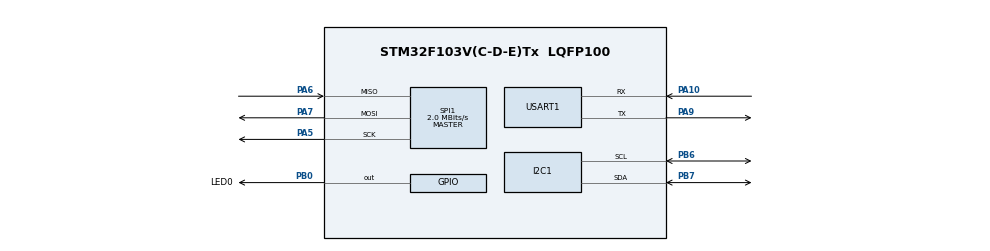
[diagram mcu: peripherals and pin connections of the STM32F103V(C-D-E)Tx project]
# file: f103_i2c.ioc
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Mcu.Family=STM32F1
PA6.Mode=Full_Duplex_Master
PA7.Mode=Full_Duplex_Master
PA10.Mode=Asynchronous
SPI1.VirtualType=VM_MASTER
PB0.GPIO_Label=LED0
SPI1.CLKPhase=SPI_PHASE_2EDGE
ProjectManager.StackSize=0x400
PA13.Signal=SYS_JTMS-SWDIO
PA9.Mode=Asynchronous
SPI1.CLKPolarity=SPI_POLARITY_HIGH
ProjectManager.TargetToolchain=MDK-ARM V5.27
SPI1.Direction=SPI_DIRECTION_2LINES
PA9.Signal=USART1_TX
PB6.Signal=I2C1_SCL
PB6.Mode=I2C
SPI1.CalculateBaudRate=2.0 MBits/s
PA5.Signal=SPI1_SCK
board=custom
RCC.APB2Freq_Value=8000000
SPI1.CRCCalculation=SPI_CRCCALCULATION_DISABLE
SPI1.Mode=SPI_MODE_MASTER
PA14.Mode=Serial_Wire
PB7.Signal=I2C1_SDA
PA13.Mode=Serial_Wire
Mcu.Name=STM32F103V(C-D-E)Tx
Mcu.Package=LQFP100
PA6.Signal=SPI1_MISO
USART1.VirtualMode=VM_ASYNC
PB7.Mode=I2C
PA10.Signal=USART1_RX
PA14.Signal=SYS_JTCK-SWCLK
ProjectManager.HeapSize=0x200
NVIC.PriorityGroup=NVIC_PRIORITYGROUP_4
RCC.APB1Freq_Value=8000000
SPI1.BaudRatePrescaler=SPI_BAUDRATEPRESCALER_4
PB0.Signal=GPIO_Output
PA5.Mode=Full_Duplex_Master
PA7.Signal=SPI1_MOSI

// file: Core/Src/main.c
/* USER CODE BEGIN Header */
/**
  ******************************************************************************
  * @file           : main.c
  * @brief          : Main program body
  ******************************************************************************
  * @attention
  *
  * <h2><center>&copy; Copyright (c) 2020 STMicroelectronics.
  * All rights reserved.</center></h2>
  *
  * This software component is licensed by ST under BSD 3-Clause license,
  * the "License"; You may not use this file except in compliance with the
  * License. You may obtain a copy of the License at:
  *                        opensource.org/licenses/BSD-3-Clause
  *
  ******************************************************************************
  */
/* USER CODE END Header */

#include "main.h"
#include "i2c.h"
#include "spi.h"
#include "usart.h"
#include "gpio.h"

/* USER CODE BEGIN Includes */
#include <string.h>

#define BufferSize 256
uint8_t WriteBuffer[BufferSize],ReadBuffer[BufferSize];
uint16_t i;
/* USER CODE END Includes */

/* USER CODE BEGIN PM */
void I2C_Test(void);
/* USER CODE END PM */

void SystemClock_Config(void);

int main(void)
{

  /* MCU Configuration--------------------------------------------------------*/

  /* Reset of all peripherals, Initializes the Flash interface and the Systick. */
  HAL_Init();

  /* Configure the system clock */
  SystemClock_Config();

  /* Initialize all configured peripherals */
  MX_GPIO_Init();
  MX_I2C1_Init();
  MX_USART1_UART_Init();
  MX_SPI1_Init();
  /* USER CODE BEGIN 2 */
	printf(" ke za zheng\n");

	//I2C_Test();
	/* Get SPI Flash ID */
	uint32_t DeviceID = SPI_FLASH_ReadDeviceID();
	printf("\r\n Manufacturer Device ID is 0x%X\r\n", DeviceID);
  /* USER CODE END 2 */

  /* Infinite loop */
  while (1)
  {

  }
}

void SystemClock_Config(void)
{
  RCC_OscInitTypeDef RCC_OscInitStruct = {0};
  RCC_ClkInitTypeDef RCC_ClkInitStruct = {0};

  /** Initializes the CPU, AHB and APB busses clocks
  */
  RCC_OscInitStruct.OscillatorType = RCC_OSCILLATORTYPE_HSI;
  RCC_OscInitStruct.HSIState = RCC_HSI_ON;
  RCC_OscInitStruct.HSICalibrationValue = RCC_HSICALIBRATION_DEFAULT;
  RCC_OscInitStruct.PLL.PLLState = RCC_PLL_NONE;
  if (HAL_RCC_OscConfig(&RCC_OscInitStruct) != HAL_OK)
  {
    Error_Handler();
  }
  /** Initializes the CPU, AHB and APB busses clocks
  */
  RCC_ClkInitStruct.ClockType = RCC_CLOCKTYPE_HCLK|RCC_CLOCKTYPE_SYSCLK
                              |RCC_CLOCKTYPE_PCLK1|RCC_CLOCKTYPE_PCLK2;
  RCC_ClkInitStruct.SYSCLKSource = RCC_SYSCLKSOURCE_HSI;
  RCC_ClkInitStruct.AHBCLKDivider = RCC_SYSCLK_DIV1;
  RCC_ClkInitStruct.APB1CLKDivider = RCC_HCLK_DIV1;
  RCC_ClkInitStruct.APB2CLKDivider = RCC_HCLK_DIV1;

  if (HAL_RCC_ClockConfig(&RCC_ClkInitStruct, FLASH_LATENCY_0) != HAL_OK)
  {
    Error_Handler();
  }
}

/* USER CODE BEGIN 4 */
void I2C_Test(void)
{
//	for(i=0; i<256; i++)
//  WriteBuffer[i]=i;    /* WriteBuffer init */
//
//	for (int j=0; j<32; j++)
//  {
//		if(HAL_I2C_Mem_Write(&hi2c1, ADDR_24LCxx_Write, 8*j, I2C_MEMADD_SIZE_8BIT,WriteBuffer+8*j,1, 1000) == HAL_OK)
//		{
//			printf("\r\n EEPROM 24C02 Write Test OK \r\n");
//			HAL_Delay(20);
//		}
//		else
//		{
//			HAL_Delay(20);
//			printf("\r\n EEPROM 24C02 Write Test False \r\n");
//		}
//	}
//	I2C1_Write(0x04,0xff);
//	HAL_Delay(10);
//
//	HAL_I2C_Mem_Read(&hi2c1, ADDR_24LCxx_Read, 0, I2C_MEMADD_SIZE_8BIT,ReadBuffer,BufferSize, 0xff);
//
//	for(i=0; i<256; i++)
//		printf("0x%02X  ",ReadBuffer[i]);

	uint8_t data;
	data=I2C1_Read(0x00);
	printf("\n %d",data);
}
/* USER CODE END 4 */

void Error_Handler(void)
{
}

/************************ (C) COPYRIGHT STMicroelectronics *****END OF FILE****/
